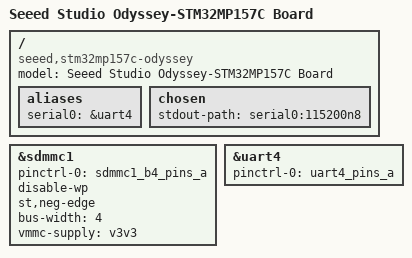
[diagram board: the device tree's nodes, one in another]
/*
 * Copyright (C) 2019, STMicroelectronics. All Rights Reserved.
 * Copyright (C) 2021, Grzegorz Szymaszek.
 *
 * SPDX-License-Identifier: (GPL-2.0-or-later OR BSD-3-Clause)
 */

/dts-v1/;

#include "stm32mp157c-odyssey-som.dtsi"

/ {
	model = "Seeed Studio Odyssey-STM32MP157C Board";
	compatible = "seeed,stm32mp157c-odyssey",
		     "seeed,stm32mp157c-odyssey-som", "st,stm32mp157";

	aliases {
		serial0 = &uart4;
	};

	chosen {
		stdout-path = "serial0:115200n8";
	};
};

&sdmmc1 {
	pinctrl-names = "default";
	pinctrl-0 = <&sdmmc1_b4_pins_a>;
	disable-wp;
	st,neg-edge;
	bus-width = <4>;
	vmmc-supply = <&v3v3>;
	status = "okay";
};

&uart4 {
	pinctrl-names = "default";
	pinctrl-0 = <&uart4_pins_a>;
	status = "okay";
};
